# STM32F410 register map
File version: 1.3
CPU: CM4 r0p1, little endian, MPU, FPU, 4 interrupt priority bits
Registers are 32-bit, read-write, reset 0x0 unless marked. A register's access mark holds for its fields unless they carry their own. Offsets are from the block's base; [hi:lo] are bit positions.

## LPTIM1 — Low power timer
Base 0x40002400
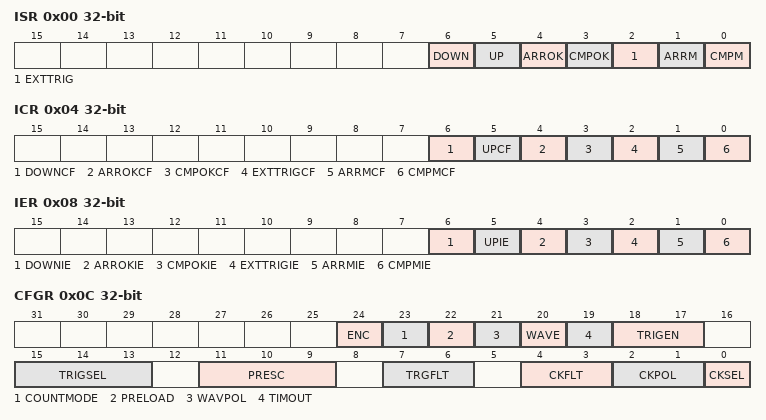
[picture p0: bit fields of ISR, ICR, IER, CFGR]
0x00 ISR ro — Interrupt and Status Register
  [6] DOWN — Counter direction change up to down
  [5] UP — Counter direction change down to up
  [4] ARROK — Autoreload register update OK
  [3] CMPOK — Compare register update OK
  [2] EXTTRIG — External trigger edge event
  [1] ARRM — Autoreload match
  [0] CMPM — Compare match
0x04 ICR wo — Interrupt Clear Register
  [6] DOWNCF — Direction change to down Clear Flag
  [5] UPCF — Direction change to UP Clear Flag
  [4] ARROKCF — Autoreload register update OK Clear Flag
  [3] CMPOKCF — Compare register update OK Clear Flag
  [2] EXTTRIGCF — External trigger valid edge Clear Flag
  [1] ARRMCF — Autoreload match Clear Flag
  [0] CMPMCF — compare match Clear Flag
0x08 IER — Interrupt Enable Register
  [6] DOWNIE — Direction change to down Interrupt Enable
  [5] UPIE — Direction change to UP Interrupt Enable
  [4] ARROKIE — Autoreload register update OK Interrupt Enable
  [3] CMPOKIE — Compare register update OK Interrupt Enable
  [2] EXTTRIGIE — External trigger valid edge Interrupt Enable
  [1] ARRMIE — Autoreload match Interrupt Enable
  [0] CMPMIE — Compare match Interrupt Enable
0x0C CFGR — Configuration Register
  [24] ENC — Encoder mode enable
  [23] COUNTMODE — counter mode enabled
  [22] PRELOAD — Registers update mode
  [21] WAVPOL — Waveform shape polarity
  [20] WAVE — Waveform shape
  [19] TIMOUT — Timeout enable
  [18:17] TRIGEN — Trigger enable and polarity
  [15:13] TRIGSEL — Trigger selector
  [11:9] PRESC — Clock prescaler
  [7:6] TRGFLT — Configurable digital filter for trigger
  [4:3] CKFLT — Configurable digital filter for external clock
  [2:1] CKPOL — Clock Polarity
  [0] CKSEL — Clock selector
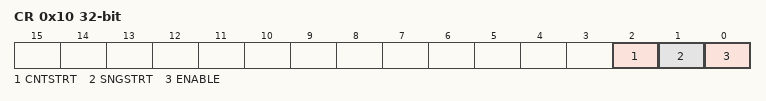
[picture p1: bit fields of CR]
0x10 CR — Control Register
  [2] CNTSTRT — Timer start in continuous mode
  [1] SNGSTRT — LPTIM start in single mode
  [0] ENABLE — LPTIM Enable
0x14 CMP — Compare Register
  [15:0] CMP — Compare value
0x18 ARR reset 0x1 — Autoreload Register
  [15:0] ARR — Auto reload value
0x1C CNT ro — Counter Register
  [15:0] CNT — Counter value
0x20 OPTR — Option Register
  [1:0] OR

## I2C4 — Inter-integrated circuit
Base 0x40006000
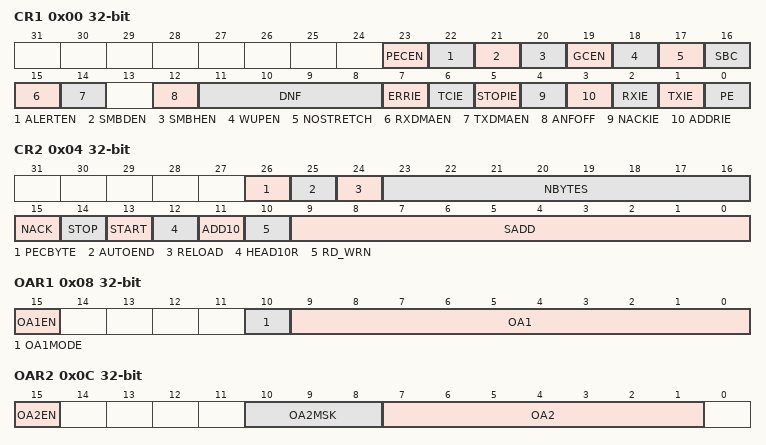
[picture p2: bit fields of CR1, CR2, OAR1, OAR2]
0x00 CR1 — Control register 1
  [23] PECEN — PEC enable
  [22] ALERTEN — SMBUS alert enable
  [21] SMBDEN — SMBus Device Default address enable
  [20] SMBHEN — SMBus Host address enable
  [19] GCEN — General call enable
  [18] WUPEN — Wakeup from STOP enable
  [17] NOSTRETCH — Clock stretching disable
  [16] SBC — Slave byte control
  [15] RXDMAEN — DMA reception requests enable
  [14] TXDMAEN — DMA transmission requests enable
  [12] ANFOFF — Analog noise filter OFF
  [11:8] DNF — Digital noise filter
  [7] ERRIE — Error interrupts enable
  [6] TCIE — Transfer Complete interrupt enable
  [5] STOPIE — STOP detection Interrupt enable
  [4] NACKIE — Not acknowledge received interrupt enable
  [3] ADDRIE — Address match interrupt enable (slave only)
  [2] RXIE — RX Interrupt enable
  [1] TXIE — TX Interrupt enable
  [0] PE — Peripheral enable
0x04 CR2 — Control register 2
  [26] PECBYTE — Packet error checking byte
  [25] AUTOEND — Automatic end mode (master mode)
  [24] RELOAD — NBYTES reload mode
  [23:16] NBYTES — Number of bytes
  [15] NACK — NACK generation (slave mode)
  [14] STOP — Stop generation (master mode)
  [13] START — Start generation
  [12] HEAD10R — 10-bit address header only read direction (master receiver mode)
  [11] ADD10 — 10-bit addressing mode (master mode)
  [10] RD_WRN — Transfer direction (master mode)
  [9:0] SADD — Slave address bit (master mode)
0x08 OAR1 — Own address register 1
  [15] OA1EN — Own Address 1 enable
  [10] OA1MODE — Own Address 1 10-bit mode
  [9:0] OA1 — Interface address
0x0C OAR2 — Own address register 2
  [15] OA2EN — Own Address 2 enable
  [10:8] OA2MSK — Own Address 2 masks
  [7:1] OA2 — Interface address
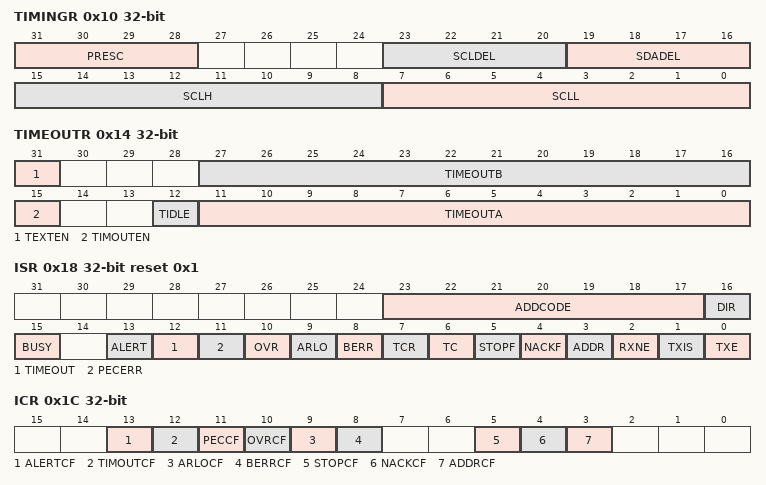
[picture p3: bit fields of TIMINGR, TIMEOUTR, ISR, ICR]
0x10 TIMINGR — Timing register
  [31:28] PRESC — Timing prescaler
  [23:20] SCLDEL — Data setup time
  [19:16] SDADEL — Data hold time
  [15:8] SCLH — SCL high period (master mode)
  [7:0] SCLL — SCL low period (master mode)
0x14 TIMEOUTR — Status register 1
  [31] TEXTEN — Extended clock timeout enable
  [27:16] TIMEOUTB — Bus timeout B
  [15] TIMOUTEN — Clock timeout enable
  [12] TIDLE — Idle clock timeout detection
  [11:0] TIMEOUTA — Bus timeout A
0x18 ISR access per field reset 0x1 — Interrupt and Status register
  [23:17] ADDCODE ro — Address match code (Slave mode)
  [16] DIR ro — Transfer direction (Slave mode)
  [15] BUSY ro — Bus busy
  [13] ALERT ro — SMBus alert
  [12] TIMEOUT ro — Timeout or t_low detection flag
  [11] PECERR ro — PEC Error in reception
  [10] OVR ro — Overrun/Underrun (slave mode)
  [9] ARLO ro — Arbitration lost
  [8] BERR ro — Bus error
  [7] TCR ro — Transfer Complete Reload
  [6] TC ro — Transfer Complete (master mode)
  [5] STOPF ro — Stop detection flag
  [4] NACKF ro — Not acknowledge received flag
  [3] ADDR ro — Address matched (slave mode)
  [2] RXNE ro — Receive data register not empty (receivers)
  [1] TXIS rw — Transmit interrupt status (transmitters)
  [0] TXE rw — Transmit data register empty (transmitters)
0x1C ICR wo — Interrupt clear register
  [13] ALERTCF — Alert flag clear
  [12] TIMOUTCF — Timeout detection flag clear
  [11] PECCF — PEC Error flag clear
  [10] OVRCF — Overrun/Underrun flag clear
  [9] ARLOCF — Arbitration lost flag clear
  [8] BERRCF — Bus error flag clear
  [5] STOPCF — Stop detection flag clear
  [4] NACKCF — Not Acknowledge flag clear
  [3] ADDRCF — Address Matched flag clear
0x20 PECR ro — PEC register
  [7:0] PEC — Packet error checking register
0x24 RXDR ro — Receive data register
  [7:0] RXDATA — 8-bit receive data
0x28 TXDR — Transmit data register
  [7:0] TXDATA — 8-bit transmit data

## FPU — Floting point unit
Base 0xE000EF34
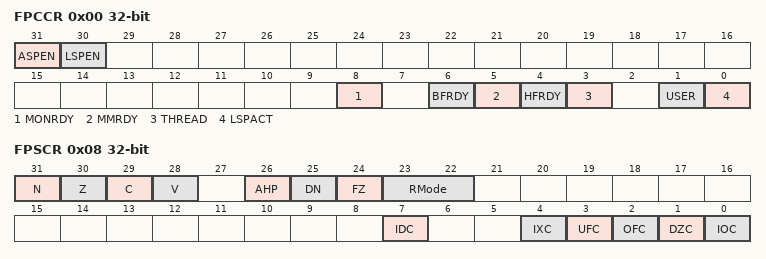
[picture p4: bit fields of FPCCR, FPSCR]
0x00 FPCCR — Floating-point context control register
  [31] ASPEN, [30] LSPEN, [8] MONRDY, [6] BFRDY, [5] MMRDY, [4] HFRDY, [3] THREAD, [1] USER, [0] LSPACT
0x04 FPCAR — Floating-point context address register
  [31:3] ADDRESS — Location of unpopulated floating-point
0x08 FPSCR — Floating-point status control register
  [31] N — Negative condition code flag
  [30] Z — Zero condition code flag
  [29] C — Carry condition code flag
  [28] V — Overflow condition code flag
  [26] AHP — Alternative half-precision control bit
  [25] DN — Default NaN mode control bit
  [24] FZ — Flush-to-zero mode control bit:
  [23:22] RMode — Rounding Mode control field
  [7] IDC — Input denormal cumulative exception bit.
  [4] IXC — Inexact cumulative exception bit
  [3] UFC — Underflow cumulative exception bit
  [2] OFC — Overflow cumulative exception bit
  [1] DZC — Division by zero cumulative exception bit.
  [0] IOC — Invalid operation cumulative exception bit

## MPU — Memory protection unit
Base 0xE000ED90
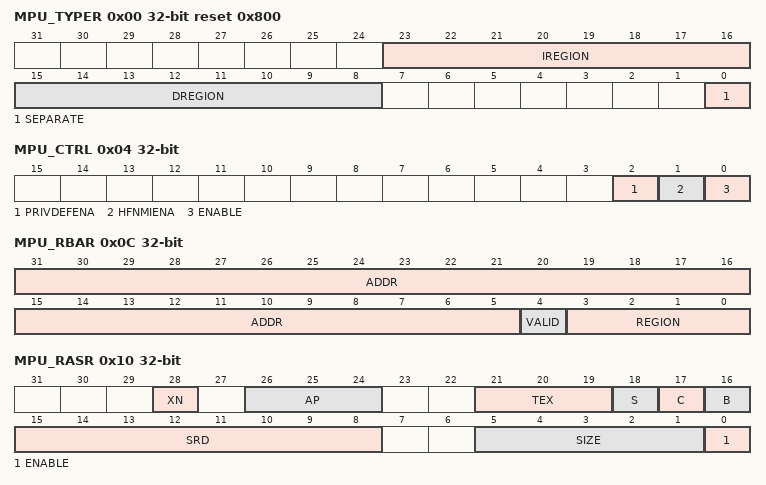
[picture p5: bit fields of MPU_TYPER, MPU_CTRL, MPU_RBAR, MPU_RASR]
0x00 MPU_TYPER ro reset 0x800 — MPU type register
  [23:16] IREGION — Number of MPU instruction regions
  [15:8] DREGION — Number of MPU data regions
  [0] SEPARATE — Separate flag
0x04 MPU_CTRL — MPU control register
  [2] PRIVDEFENA — Enable priviliged software access to default memory map
  [1] HFNMIENA — Enables the operation of MPU during hard fault
  [0] ENABLE — Enables the MPU
0x08 MPU_RNR — MPU region number register
  [7:0] REGION — MPU region
0x0C MPU_RBAR — MPU region base address register
  [31:5] ADDR — Region base address field
  [4] VALID — MPU region number valid
  [3:0] REGION — MPU region field
0x10 MPU_RASR — MPU region attribute and size register
  [28] XN — Instruction access disable bit
  [26:24] AP — Access permission
  [21:19] TEX — memory attribute
  [18] S — Shareable memory attribute
  [17] C — memory attribute
  [16] B — memory attribute
  [15:8] SRD — Subregion disable bits
  [5:1] SIZE — Size of the MPU protection region
  [0] ENABLE — Region enable bit.

## STK — SysTick timer
Base 0xE000E010
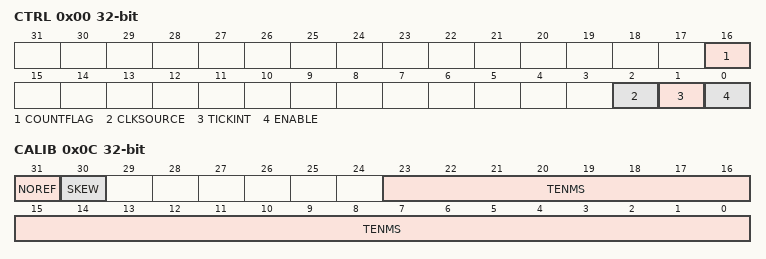
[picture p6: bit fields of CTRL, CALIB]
0x00 CTRL — SysTick control and status register
  [16] COUNTFLAG
  [2] CLKSOURCE — Clock source selection
  [1] TICKINT — SysTick exception request enable
  [0] ENABLE — Counter enable
0x04 LOAD — SysTick reload value register
  [23:0] RELOAD — RELOAD value
0x08 VAL — SysTick current value register
  [23:0] CURRENT — Current counter value
0x0C CALIB — SysTick calibration value register
  [31] NOREF — NOREF flag. Reads as zero
  [30] SKEW — SKEW flag: Indicates whether the TENMS value is exact
  [23:0] TENMS — Calibration value

## NVIC_STIR — Nested vectored interrupt controller
Base 0xE000EF00
0x00 STIR — Software trigger interrupt register
  [8:0] INTID — Software generated interrupt ID

## FPU_CPACR — Floating point unit CPACR
Base 0xE000ED88
0x00 CPACR — Coprocessor access control register
  [23:20] CP

## SCB_ACTRL — System control block ACTLR
Base 0xE000E008
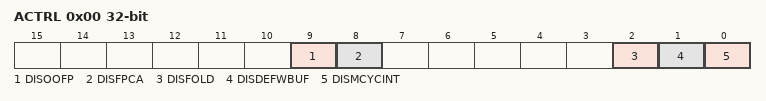
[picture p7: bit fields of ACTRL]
0x00 ACTRL — Auxiliary control register
  [9] DISOOFP, [8] DISFPCA, [2] DISFOLD, [1] DISDEFWBUF, [0] DISMCYCINT
